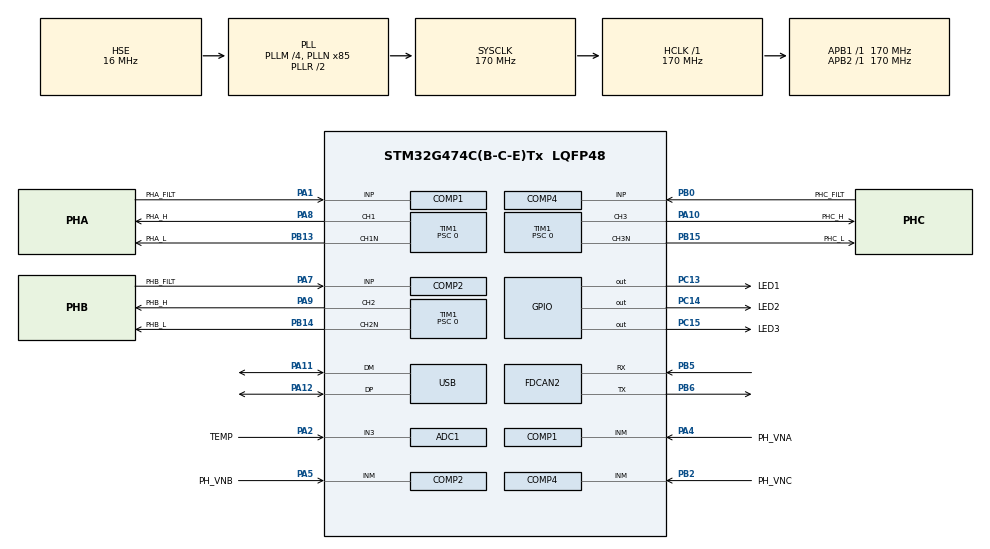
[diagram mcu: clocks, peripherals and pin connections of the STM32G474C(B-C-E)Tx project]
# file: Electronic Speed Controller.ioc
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ADC1.Channel-1\#ChannelRegularConversion=ADC_CHANNEL_3
ADC1.NbrOfConversionFlag=1
ADC1.OffsetNumber-1\#ChannelRegularConversion=ADC_OFFSET_NONE
ADC1.Rank-1\#ChannelRegularConversion=1
ADC1.SamplingTime-1\#ChannelRegularConversion=ADC_SAMPLETIME_2CYCLES_5
ADC1.master=1
COMP1.BlankingSrce=COMP_BLANKINGSRC_NONE
COMP1.Hysteresis=COMP_HYSTERESIS_50MV
COMP1.TriggerMode=COMP_TRIGGERMODE_NONE
COMP2.BlankingSrce=COMP_BLANKINGSRC_NONE
COMP2.Hysteresis=COMP_HYSTERESIS_50MV
COMP2.TriggerMode=COMP_TRIGGERMODE_NONE
COMP4.BlankingSrce=COMP_BLANKINGSRC_NONE
COMP4.Hysteresis=COMP_HYSTERESIS_50MV
COMP4.TriggerMode=COMP_TRIGGERMODE_NONE
FDCAN2.AutoRetransmission=ENABLE
FDCAN2.CalculateBaudRateNominal=999999
FDCAN2.CalculateTimeBitNominal=1000
FDCAN2.CalculateTimeQuantumNominal=58.82352941176471
FDCAN2.NominalPrescaler=10
FDCAN2.NominalTimeSeg1=13
FDCAN2.NominalTimeSeg2=3
FDCAN2.StdFiltersNbr=1
FDCAN2.TransmitPause=ENABLE
FREERTOS.Queues01=threadInputQueue,64,ThreadInput,0,Static,threadInputQueueBuffer,threadInputQueueControlBlock
FREERTOS.Tasks01=mainTask,24,1024,start_main_task,Default,NULL,Static,mainTaskBuffer,mainTaskControlBlock
FREERTOS.configENABLE_FPU=1
FREERTOS.configMAX_TASK_NAME_LEN=32
FREERTOS.configMINIMAL_STACK_SIZE=512
FREERTOS.configTOTAL_HEAP_SIZE=32768
FREERTOS.configUSE_NEWLIB_REENTRANT=1
Mcu.Family=STM32G4
Mcu.Name=STM32G474C(B-C-E)Tx
Mcu.Package=LQFP48
NVIC.FDCAN2_IT0_IRQn=true\:5\:0\:false\:false\:true\:true\:true\:true\:true
NVIC.FDCAN2_IT1_IRQn=true\:5\:0\:false\:false\:true\:true\:true\:true\:true
NVIC.PriorityGroup=NVIC_PRIORITYGROUP_4
NVIC.TIM1_BRK_TIM15_IRQn=true\:5\:0\:false\:false\:true\:true\:true\:true\:true
NVIC.TIM1_CC_IRQn=true\:5\:0\:false\:false\:true\:true\:true\:true\:true
NVIC.TIM1_TRG_COM_TIM17_IRQn=true\:5\:0\:false\:false\:true\:true\:true\:true\:true
NVIC.TIM1_UP_TIM16_IRQn=true\:5\:0\:false\:false\:true\:true\:true\:true\:true
NVIC.TIM3_IRQn=true\:15\:0\:false\:false\:true\:false\:false\:true\:true
NVIC.TimeBase=TIM3_IRQn
NVIC.TimeBaseIP=TIM3
PA1.GPIO_Label=PHA_FILT
PA1.Mode=INP
PA1.Signal=COMP1_INP
PA10.GPIO_Label=PHC_H
PA10.Signal=S_TIM1_CH3
PA11.Mode=Device
PA11.Signal=USB_DM
PA12.Mode=Device
PA12.Signal=USB_DP
PA13.Mode=Trace_Asynchronous_SW
PA13.Signal=SYS_JTMS-SWDIO
PA14.Mode=Trace_Asynchronous_SW
PA14.Signal=SYS_JTCK-SWCLK
PA2.GPIO_Label=TEMP
PA2.Mode=IN3-Single-Ended
PA2.Signal=ADC1_IN3
PA4.GPIO_Label=PH_VNA
PA4.Mode=INM
PA4.Signal=COMP1_INM
PA5.GPIO_Label=PH_VNB
PA5.Mode=INM
PA5.Signal=COMP2_INM
PA7.GPIO_Label=PHB_FILT
PA7.Mode=INP
PA7.Signal=COMP2_INP
PA8.GPIO_Label=PHA_H
PA8.Signal=S_TIM1_CH1
PA9.GPIO_Label=PHB_H
PA9.Signal=S_TIM1_CH2
PB0.GPIO_Label=PHC_FILT
PB0.Mode=INP
PB0.Signal=COMP4_INP
PB13.GPIO_Label=PHA_L
PB13.Mode=PWM Generation1 CH1 CH1N
PB13.Signal=TIM1_CH1N
PB14.GPIO_Label=PHB_L
PB14.Mode=PWM Generation2 CH2 CH2N
PB14.Signal=TIM1_CH2N
PB15.GPIO_Label=PHC_L
PB15.Mode=PWM Generation3 CH3 CH3N
PB15.Signal=TIM1_CH3N
PB2.GPIO_Label=PH_VNC
PB2.Mode=INM
PB2.Signal=COMP4_INM
PB3.Mode=Trace_Asynchronous_SW
PB3.Signal=SYS_JTDO-SWO
PB5.Mode=FDCAN_Activate
PB5.Signal=FDCAN2_RX
PB6.Mode=FDCAN_Activate
PB6.Signal=FDCAN2_TX
PC13.GPIO_Label=LED1
PC13.PinState=GPIO_PIN_RESET
PC13.Signal=GPIO_Output
PC14-OSC32_IN.GPIO_Label=LED2
PC14-OSC32_IN.PinState=GPIO_PIN_RESET
PC14-OSC32_IN.Signal=GPIO_Output
PC15-OSC32_OUT.GPIO_Label=LED3
PC15-OSC32_OUT.PinState=GPIO_PIN_RESET
PC15-OSC32_OUT.Signal=GPIO_Output
PF0-OSC_IN.Mode=HSE-External-Oscillator
PF0-OSC_IN.Signal=RCC_OSC_IN
PF1-OSC_OUT.Mode=HSE-External-Oscillator
PF1-OSC_OUT.Signal=RCC_OSC_OUT
ProjectManager.HeapSize=0x200
ProjectManager.StackSize=0x400
ProjectManager.TargetToolchain=STM32CubeIDE
RCC.ADC12Freq_Value=170000000
RCC.ADC345Freq_Value=170000000
RCC.AHBFreq_Value=170000000
RCC.APB1Freq_Value=170000000
RCC.APB1TimFreq_Value=170000000
RCC.APB2Freq_Value=170000000
RCC.APB2TimFreq_Value=170000000
RCC.CK48CLockSelection=RCC_USBCLKSOURCE_HSI48
RCC.CortexFreq_Value=170000000
RCC.EXTERNAL_CLOCK_VALUE=12288000
RCC.HCLKFreq_Value=170000000
RCC.HSE_VALUE=16000000
RCC.HSI48_VALUE=48000000
RCC.HSI_VALUE=16000000
RCC.LSE_VALUE=32768
RCC.PLLM=RCC_PLLM_DIV4
RCC.PLLN=85
RCC.PLLSourceVirtual=RCC_PLLSOURCE_HSE
RCC.SYSCLKFreq_VALUE=170000000
RCC.SYSCLKSource=RCC_SYSCLKSOURCE_PLLCLK
RCC.USBFreq_Value=48000000
RCC.VCOOutputFreq_Value=340000000
SH.S_TIM1_CH1.0=TIM1_CH1,PWM Generation1 CH1 CH1N
SH.S_TIM1_CH2.0=TIM1_CH2,PWM Generation2 CH2 CH2N
SH.S_TIM1_CH3.0=TIM1_CH3,PWM Generation3 CH3 CH3N
TIM1.AutoReloadPreload=TIM_AUTORELOAD_PRELOAD_ENABLE
TIM1.AutomaticOutput=TIM_AUTOMATICOUTPUT_ENABLE
TIM1.Channel-PWM\ Generation1\ CH1\ CH1N=TIM_CHANNEL_1
TIM1.Channel-PWM\ Generation2\ CH2\ CH2N=TIM_CHANNEL_2
TIM1.Channel-PWM\ Generation3\ CH3\ CH3N=TIM_CHANNEL_3
TIM1.Channel-PWM\ Generation4\ No\ Output=TIM_CHANNEL_4
TIM1.DeadTime=85
TIM1.OffStateIDLEMode=TIM_OSSI_ENABLE
TIM1.OffStateRunMode=TIM_OSSR_ENABLE
TIM1.PeriodNoDither=5312-1
TIM1.Prescaler=0
TIM1.PulseNoDither_1=0
TIM1.TIM_MasterSlaveMode=TIM_MASTERSLAVEMODE_DISABLE
TIM2.AutoReloadPreload=TIM_AUTORELOAD_PRELOAD_ENABLE
TIM2.PeriodNoDither=0xFFFFFFFF-1
TIM2.Prescaler=170-1
VP_FREERTOS_VS_CMSIS_V2.Mode=CMSIS_V2
VP_SYS_VS_DBSignals.Mode=DisableDeadBatterySignals
VP_SYS_VS_tim3.Mode=TIM3
VP_TIM1_VS_ClockSourceINT.Mode=Internal
VP_TIM1_VS_no_output4.Mode=PWM Generation4 No Output
VP_TIM2_VS_ClockSourceINT.Mode=Internal
board=custom

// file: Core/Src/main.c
/* USER CODE BEGIN Header */
/**
  ******************************************************************************
  * @file           : main.c
  * @brief          : Main program body
  ******************************************************************************
  * @attention
  *
  * Copyright (c) 2024 STMicroelectronics.
  * All rights reserved.
  *
  * This software is licensed under terms that can be found in the LICENSE file
  * in the root directory of this software component.
  * If no LICENSE file comes with this software, it is provided AS-IS.
  *
  ******************************************************************************
  */
/* USER CODE END Header */
#include "main.h"
#include "cmsis_os.h"
#include "adc.h"
#include "comp.h"
#include "fdcan.h"
#include "tim.h"
#include "usb.h"
#include "gpio.h"

void SystemClock_Config(void);
void MX_FREERTOS_Init(void);

int main(void)
{

  /* MCU Configuration--------------------------------------------------------*/

  /* Reset of all peripherals, Initializes the Flash interface and the Systick. */
  HAL_Init();

  /* Configure the system clock */
  SystemClock_Config();

  /* Initialize all configured peripherals */
  MX_GPIO_Init();
  MX_COMP1_Init();
  MX_COMP2_Init();
  MX_COMP4_Init();
  MX_FDCAN2_Init();
  MX_TIM1_Init();
  MX_USB_PCD_Init();
  MX_ADC1_Init();
  MX_TIM2_Init();

  /* Init scheduler */
  osKernelInitialize();

  /* Call init function for freertos objects (in cmsis_os2.c) */
  MX_FREERTOS_Init();

  /* Start scheduler */
  osKernelStart();

  /* We should never get here as control is now taken by the scheduler */

  /* Infinite loop */
  while (1)
  {

  }
}

void SystemClock_Config(void)
{
  RCC_OscInitTypeDef RCC_OscInitStruct = {0};
  RCC_ClkInitTypeDef RCC_ClkInitStruct = {0};

  /** Configure the main internal regulator output voltage
  */
  HAL_PWREx_ControlVoltageScaling(PWR_REGULATOR_VOLTAGE_SCALE1_BOOST);

  /** Initializes the RCC Oscillators according to the specified parameters
  * in the RCC_OscInitTypeDef structure.
  */
  RCC_OscInitStruct.OscillatorType = RCC_OSCILLATORTYPE_HSI48|RCC_OSCILLATORTYPE_HSE;
  RCC_OscInitStruct.HSEState = RCC_HSE_ON;
  RCC_OscInitStruct.HSI48State = RCC_HSI48_ON;
  RCC_OscInitStruct.PLL.PLLState = RCC_PLL_ON;
  RCC_OscInitStruct.PLL.PLLSource = RCC_PLLSOURCE_HSE;
  RCC_OscInitStruct.PLL.PLLM = RCC_PLLM_DIV4;
  RCC_OscInitStruct.PLL.PLLN = 85;
  RCC_OscInitStruct.PLL.PLLP = RCC_PLLP_DIV2;
  RCC_OscInitStruct.PLL.PLLQ = RCC_PLLQ_DIV2;
  RCC_OscInitStruct.PLL.PLLR = RCC_PLLR_DIV2;
  if (HAL_RCC_OscConfig(&RCC_OscInitStruct) != HAL_OK)
  {
    Error_Handler();
  }

  /** Initializes the CPU, AHB and APB buses clocks
  */
  RCC_ClkInitStruct.ClockType = RCC_CLOCKTYPE_HCLK|RCC_CLOCKTYPE_SYSCLK
                              |RCC_CLOCKTYPE_PCLK1|RCC_CLOCKTYPE_PCLK2;
  RCC_ClkInitStruct.SYSCLKSource = RCC_SYSCLKSOURCE_PLLCLK;
  RCC_ClkInitStruct.AHBCLKDivider = RCC_SYSCLK_DIV1;
  RCC_ClkInitStruct.APB1CLKDivider = RCC_HCLK_DIV1;
  RCC_ClkInitStruct.APB2CLKDivider = RCC_HCLK_DIV1;

  if (HAL_RCC_ClockConfig(&RCC_ClkInitStruct, FLASH_LATENCY_4) != HAL_OK)
  {
    Error_Handler();
  }
}

void HAL_TIM_PeriodElapsedCallback(TIM_HandleTypeDef *htim)
{
  if (htim->Instance == TIM3) {
    HAL_IncTick();
  }
}

void Error_Handler(void)
{
  __disable_irq();
  while (1)
  {
  }
}

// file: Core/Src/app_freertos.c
/* USER CODE BEGIN Header */
/**
  ******************************************************************************
  * File Name          : app_freertos.c
  * Description        : Code for freertos applications
  ******************************************************************************
  * @attention
  *
  * Copyright (c) 2026 STMicroelectronics.
  * All rights reserved.
  *
  * This software is licensed under terms that can be found in the LICENSE file
  * in the root directory of this software component.
  * If no LICENSE file comes with this software, it is provided AS-IS.
  *
  ******************************************************************************
  */
/* USER CODE END Header */

#include "FreeRTOS.h"
#include "task.h"
#include "main.h"
#include "cmsis_os.h"

/* USER CODE BEGIN Includes */

#include "Threads/main_thread.hpp"
#include "Threads/main_thread_types.hpp"

/* USER CODE END Includes */

typedef StaticTask_t osStaticThreadDef_t;
typedef StaticQueue_t osStaticMessageQDef_t;

/* Definitions for mainTask */
osThreadId_t mainTaskHandle;
uint32_t mainTaskBuffer[ 1024 ];
osStaticThreadDef_t mainTaskControlBlock;
const osThreadAttr_t mainTask_attributes = {
  .name = "mainTask",
  .stack_mem = &mainTaskBuffer[0],
  .stack_size = sizeof(mainTaskBuffer),
  .cb_mem = &mainTaskControlBlock,
  .cb_size = sizeof(mainTaskControlBlock),
  .priority = (osPriority_t) osPriorityNormal,
};
/* Definitions for threadInputQueue */
osMessageQueueId_t threadInputQueueHandle;
uint8_t threadInputQueueBuffer[ 64 * sizeof( ThreadInput ) ];
osStaticMessageQDef_t threadInputQueueControlBlock;
const osMessageQueueAttr_t threadInputQueue_attributes = {
  .name = "threadInputQueue",
  .cb_mem = &threadInputQueueControlBlock,
  .cb_size = sizeof(threadInputQueueControlBlock),
  .mq_mem = &threadInputQueueBuffer,
  .mq_size = sizeof(threadInputQueueBuffer)
};

void start_main_task(void *argument);

void MX_FREERTOS_Init(void); /* (MISRA C 2004 rule 8.1) */

void MX_FREERTOS_Init(void) {

  /* Create the queue(s) */
  /* creation of threadInputQueue */
  threadInputQueueHandle = osMessageQueueNew (64, sizeof(ThreadInput), &threadInputQueue_attributes);

  /* Create the thread(s) */
  /* creation of mainTask */
  mainTaskHandle = osThreadNew(start_main_task, NULL, &mainTask_attributes);

}

void start_main_task(void *argument)
{
  /* USER CODE BEGIN start_main_task */
  /* Infinite loop */
	main_thread();
  /* USER CODE END start_main_task */
}
